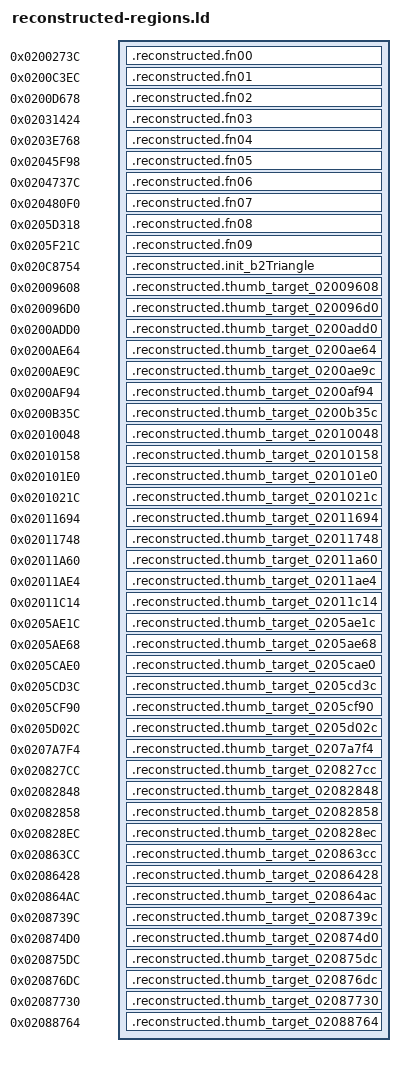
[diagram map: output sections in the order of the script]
SECTIONS
{
  reconstructed_external_arm_02012360 = 0x02012360;
  reconstructed_external_arm_02012530 = 0x02012530;
  reconstructed_external_arm_0202fa58 = 0x0202fa58;
  reconstructed_external_arm_0202fb28 = 0x0202fb28;
  reconstructed_external_arm_0203cf34 = 0x0203cf34;
  reconstructed_external_arm_0203df5c = 0x0203df5c;
  reconstructed_external_arm_02045f98 = 0x02045f98;
  reconstructed_external_arm_02045ff8 = 0x02045ff8;
  reconstructed_external_arm_02046030 = 0x02046030;
  reconstructed_external_arm_020460d8 = 0x020460d8;
  reconstructed_external_arm_02046328 = 0x02046328;
  reconstructed_external_arm_02046a2c = 0x02046a2c;
  reconstructed_external_arm_020480f0 = 0x020480f0;
  reconstructed_external_arm_02048128 = 0x02048128;
  reconstructed_external_arm_020482b0 = 0x020482b0;
  reconstructed_external_arm_020496d8 = 0x020496d8;
  reconstructed_external_arm_0204a0cc = 0x0204a0cc;
  reconstructed_external_arm_0204c154 = 0x0204c154;
  reconstructed_external_arm_0205db7c = 0x0205db7c;
  reconstructed_external_arm_0205dd48 = 0x0205dd48;
  reconstructed_external_arm_0205ecbc = 0x0205ecbc;
  reconstructed_external_arm_02082c68 = 0x02082c68;
  reconstructed_external_arm_02083298 = 0x02083298;
  reconstructed_external_arm_02083618 = 0x02083618;
  reconstructed_external_arm_020836f4 = 0x020836f4;
  reconstructed_external_arm_02083a84 = 0x02083a84;
  reconstructed_external_arm_02083a9c = 0x02083a9c;
  reconstructed_external_arm_02083afc = 0x02083afc;
  reconstructed_external_arm_02097804 = 0x02097804;
  reconstructed_external_arm_02097810 = 0x02097810;
  reconstructed_external_arm_0209781c = 0x0209781c;
  reconstructed_external_arm_02097834 = 0x02097834;
  reconstructed_external_arm_0209784c = 0x0209784c;
  reconstructed_external_arm_02097858 = 0x02097858;
  reconstructed_external_arm_02097870 = 0x02097870;
  reconstructed_external_arm_0209787c = 0x0209787c;
  reconstructed_external_arm_02097888 = 0x02097888;
  reconstructed_external_arm_02097894 = 0x02097894;
  reconstructed_external_arm_020978a0 = 0x020978a0;
  reconstructed_external_arm_020978ac = 0x020978ac;
  reconstructed_external_arm_020978b8 = 0x020978b8;
  .reconstructed.fn00 0x0200273c : { *(.reconstructed.fn00) }
  .reconstructed.fn01 0x0200c3ec : { *(.reconstructed.fn01) }
  .reconstructed.fn02 0x0200d678 : { *(.reconstructed.fn02) }
  .reconstructed.fn03 0x02031424 : { *(.reconstructed.fn03) }
  .reconstructed.fn04 0x0203e768 : { *(.reconstructed.fn04) }
  .reconstructed.fn05 0x02045f98 : { *(.reconstructed.fn05) }
  .reconstructed.fn06 0x0204737c : { *(.reconstructed.fn06) }
  .reconstructed.fn07 0x020480f0 : { *(.reconstructed.fn07) }
  .reconstructed.fn08 0x0205d318 : { *(.reconstructed.fn08) }
  .reconstructed.fn09 0x0205f21c : { *(.reconstructed.fn09) }
  .reconstructed.init_b2Triangle 0x020c8754 : { *(.reconstructed.init_b2Triangle) }
  .reconstructed.thumb_target_02009608 0x02009608 : { *(.reconstructed.thumb_target_02009608) }
  .reconstructed.thumb_target_020096d0 0x020096d0 : { *(.reconstructed.thumb_target_020096d0) }
  .reconstructed.thumb_target_0200add0 0x0200add0 : { *(.reconstructed.thumb_target_0200add0) }
  .reconstructed.thumb_target_0200ae64 0x0200ae64 : { *(.reconstructed.thumb_target_0200ae64) }
  .reconstructed.thumb_target_0200ae9c 0x0200ae9c : { *(.reconstructed.thumb_target_0200ae9c) }
  .reconstructed.thumb_target_0200af94 0x0200af94 : { *(.reconstructed.thumb_target_0200af94) }
  .reconstructed.thumb_target_0200b35c 0x0200b35c : { *(.reconstructed.thumb_target_0200b35c) }
  .reconstructed.thumb_target_02010048 0x02010048 : { *(.reconstructed.thumb_target_02010048) }
  .reconstructed.thumb_target_02010158 0x02010158 : { *(.reconstructed.thumb_target_02010158) }
  .reconstructed.thumb_target_020101e0 0x020101e0 : { *(.reconstructed.thumb_target_020101e0) }
  .reconstructed.thumb_target_0201021c 0x0201021c : { *(.reconstructed.thumb_target_0201021c) }
  .reconstructed.thumb_target_02011694 0x02011694 : { *(.reconstructed.thumb_target_02011694) }
  .reconstructed.thumb_target_02011748 0x02011748 : { *(.reconstructed.thumb_target_02011748) }
  .reconstructed.thumb_target_02011a60 0x02011a60 : { *(.reconstructed.thumb_target_02011a60) }
  .reconstructed.thumb_target_02011ae4 0x02011ae4 : { *(.reconstructed.thumb_target_02011ae4) }
  .reconstructed.thumb_target_02011c14 0x02011c14 : { *(.reconstructed.thumb_target_02011c14) }
  .reconstructed.thumb_target_0205ae1c 0x0205ae1c : { *(.reconstructed.thumb_target_0205ae1c) }
  .reconstructed.thumb_target_0205ae68 0x0205ae68 : { *(.reconstructed.thumb_target_0205ae68) }
  .reconstructed.thumb_target_0205cae0 0x0205cae0 : { *(.reconstructed.thumb_target_0205cae0) }
  .reconstructed.thumb_target_0205cd3c 0x0205cd3c : { *(.reconstructed.thumb_target_0205cd3c) }
  .reconstructed.thumb_target_0205cf90 0x0205cf90 : { *(.reconstructed.thumb_target_0205cf90) }
  .reconstructed.thumb_target_0205d02c 0x0205d02c : { *(.reconstructed.thumb_target_0205d02c) }
  .reconstructed.thumb_target_0207a7f4 0x0207a7f4 : { *(.reconstructed.thumb_target_0207a7f4) }
  .reconstructed.thumb_target_020827cc 0x020827cc : { *(.reconstructed.thumb_target_020827cc) }
  .reconstructed.thumb_target_02082848 0x02082848 : { *(.reconstructed.thumb_target_02082848) }
  .reconstructed.thumb_target_02082858 0x02082858 : { *(.reconstructed.thumb_target_02082858) }
  .reconstructed.thumb_target_020828ec 0x020828ec : { *(.reconstructed.thumb_target_020828ec) }
  .reconstructed.thumb_target_020863cc 0x020863cc : { *(.reconstructed.thumb_target_020863cc) }
  .reconstructed.thumb_target_02086428 0x02086428 : { *(.reconstructed.thumb_target_02086428) }
  .reconstructed.thumb_target_020864ac 0x020864ac : { *(.reconstructed.thumb_target_020864ac) }
  .reconstructed.thumb_target_0208739c 0x0208739c : { *(.reconstructed.thumb_target_0208739c) }
  .reconstructed.thumb_target_020874d0 0x020874d0 : { *(.reconstructed.thumb_target_020874d0) }
  .reconstructed.thumb_target_020875dc 0x020875dc : { *(.reconstructed.thumb_target_020875dc) }
  .reconstructed.thumb_target_020876dc 0x020876dc : { *(.reconstructed.thumb_target_020876dc) }
  .reconstructed.thumb_target_02087730 0x02087730 : { *(.reconstructed.thumb_target_02087730) }
  .reconstructed.thumb_target_02088764 0x02088764 : { *(.reconstructed.thumb_target_02088764) }
}
